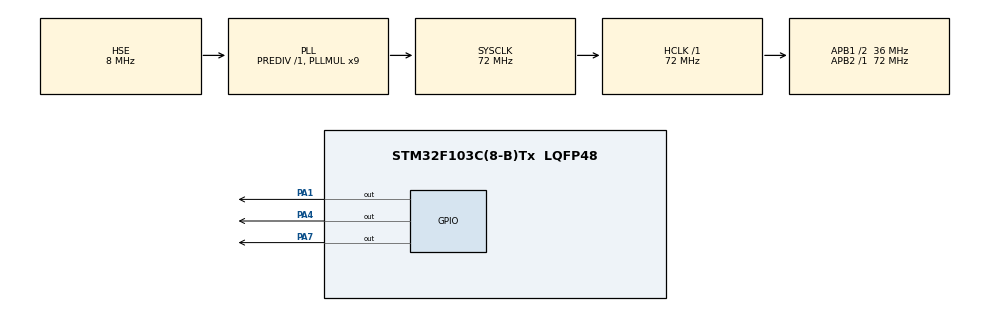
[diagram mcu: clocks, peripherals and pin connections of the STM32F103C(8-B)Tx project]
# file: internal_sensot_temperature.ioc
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ADC1.Channel-0\#ChannelRegularConversion=ADC_CHANNEL_TEMPSENSOR
ADC1.ContinuousConvMode=ENABLE
ADC1.NbrOfConversionFlag=1
ADC1.Rank-0\#ChannelRegularConversion=1
ADC1.SamplingTime-0\#ChannelRegularConversion=ADC_SAMPLETIME_55CYCLES_5
ADC1.master=1
Mcu.Family=STM32F1
Mcu.Name=STM32F103C(8-B)Tx
Mcu.Package=LQFP48
NVIC.PriorityGroup=NVIC_PRIORITYGROUP_4
PA1.Signal=GPIO_Output
PA13.Mode=Serial_Wire
PA13.Signal=SYS_JTMS-SWDIO
PA14.Mode=Serial_Wire
PA14.Signal=SYS_JTCK-SWCLK
PA4.Signal=GPIO_Output
PA7.Signal=GPIO_Output
PD0-OSC_IN.Mode=HSE-External-Oscillator
PD0-OSC_IN.Signal=RCC_OSC_IN
PD1-OSC_OUT.Mode=HSE-External-Oscillator
PD1-OSC_OUT.Signal=RCC_OSC_OUT
ProjectManager.HeapSize=0x200
ProjectManager.StackSize=0x400
ProjectManager.TargetToolchain=STM32CubeIDE
RCC.ADCPresc=RCC_ADCPCLK2_DIV6
RCC.AHBFreq_Value=72000000
RCC.APB1CLKDivider=RCC_HCLK_DIV2
RCC.APB1Freq_Value=36000000
RCC.APB1TimFreq_Value=72000000
RCC.APB2Freq_Value=72000000
RCC.APB2TimFreq_Value=72000000
RCC.HCLKFreq_Value=72000000
RCC.PLLMUL=RCC_PLL_MUL9
RCC.PLLSourceVirtual=RCC_PLLSOURCE_HSE
RCC.SYSCLKFreq_VALUE=72000000
RCC.SYSCLKSource=RCC_SYSCLKSOURCE_PLLCLK
RCC.USBFreq_Value=72000000
VP_ADC1_TempSens_Input.Mode=IN-TempSens
VP_ADC1_Vref_Input.Mode=IN-Vrefint
board=custom

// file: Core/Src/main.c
#include "main.h"

ADC_HandleTypeDef hadc1;

/* USER CODE BEGIN PV */
// Variables to store ADC reading and calculated temperatures
uint16_t readValue; // Value read from ADC
float tCelsius; // Temperature in degrees Celsius
float tFahrenheit; // Temperature in degrees Fahrenheit

/* USER CODE END PV */

void SystemClock_Config(void);
static void MX_GPIO_Init(void);
static void MX_ADC1_Init(void);

int main(void)
{

  /* MCU Configuration--------------------------------------------------------*/

  /* Reset of all peripherals, Initializes the Flash interface and the Systick. */
  HAL_Init();

  /* Configure the system clock */
  SystemClock_Config();

  /* Initialize all configured peripherals */
  MX_GPIO_Init();
  MX_ADC1_Init();
  /* USER CODE BEGIN 2 */

  // Start ADC
  HAL_ADC_Start(&hadc1);

  /* USER CODE END 2 */

  /* Infinite loop */
  /* USER CODE BEGIN WHILE */
  while (1)
  {
    // Wait for ADC to complete conversion
    HAL_ADC_PollForConversion(&hadc1, 1000);

    // Get the ADC reading and adjust by adding 60
    readValue = HAL_ADC_GetValue(&hadc1) + 60;

    // Calculate temperature in Celsius and Fahrenheit using linear formulas
    tCelsius = 357.558 - 0.187364 * readValue;
    tFahrenheit = 675.6 - 0.337255 * readValue;

    // Determine LED state based on ADC reading
    if (readValue > 1740) // High-temperature condition
    {
      HAL_GPIO_WritePin(GPIOA, GPIO_PIN_7, 1); // Red LED ON
      HAL_GPIO_WritePin(GPIOA, GPIO_PIN_4, 0); // Green LED OFF
      HAL_GPIO_WritePin(GPIOA, GPIO_PIN_1, 0); // Blue LED OFF
    }
    else if (readValue > 1720) // Medium-temperature condition
    {
      HAL_GPIO_WritePin(GPIOA, GPIO_PIN_7, 0); // Red LED OFF
      HAL_GPIO_WritePin(GPIOA, GPIO_PIN_4, 1); // Green LED ON
      HAL_GPIO_WritePin(GPIOA, GPIO_PIN_1, 0); // Blue LED OFF
    }
    else // Low-temperature condition
    {
      HAL_GPIO_WritePin(GPIOA, GPIO_PIN_7, 0); // Red LED OFF
      HAL_GPIO_WritePin(GPIOA, GPIO_PIN_4, 0); // Green LED OFF
      HAL_GPIO_WritePin(GPIOA, GPIO_PIN_1, 1); // Blue LED ON
    }

    // Wait 100 ms before the next reading
    HAL_Delay(100);

    /* USER CODE END WHILE */

  }
}

void SystemClock_Config(void)
{
  RCC_OscInitTypeDef RCC_OscInitStruct = {0};
  RCC_ClkInitTypeDef RCC_ClkInitStruct = {0};
  RCC_PeriphCLKInitTypeDef PeriphClkInit = {0};

  /** Initializes the RCC Oscillators according to the specified parameters
  * in the RCC_OscInitTypeDef structure.
  */
  RCC_OscInitStruct.OscillatorType = RCC_OSCILLATORTYPE_HSE;
  RCC_OscInitStruct.HSEState = RCC_HSE_ON;
  RCC_OscInitStruct.HSEPredivValue = RCC_HSE_PREDIV_DIV1;
  RCC_OscInitStruct.HSIState = RCC_HSI_ON;
  RCC_OscInitStruct.PLL.PLLState = RCC_PLL_ON;
  RCC_OscInitStruct.PLL.PLLSource = RCC_PLLSOURCE_HSE;
  RCC_OscInitStruct.PLL.PLLMUL = RCC_PLL_MUL9;
  if (HAL_RCC_OscConfig(&RCC_OscInitStruct) != HAL_OK)
  {
    Error_Handler();
  }

  /** Initializes the CPU, AHB and APB buses clocks
  */
  RCC_ClkInitStruct.ClockType = RCC_CLOCKTYPE_HCLK|RCC_CLOCKTYPE_SYSCLK
                              |RCC_CLOCKTYPE_PCLK1|RCC_CLOCKTYPE_PCLK2;
  RCC_ClkInitStruct.SYSCLKSource = RCC_SYSCLKSOURCE_PLLCLK;
  RCC_ClkInitStruct.AHBCLKDivider = RCC_SYSCLK_DIV1;
  RCC_ClkInitStruct.APB1CLKDivider = RCC_HCLK_DIV2;
  RCC_ClkInitStruct.APB2CLKDivider = RCC_HCLK_DIV1;

  if (HAL_RCC_ClockConfig(&RCC_ClkInitStruct, FLASH_LATENCY_2) != HAL_OK)
  {
    Error_Handler();
  }
  PeriphClkInit.PeriphClockSelection = RCC_PERIPHCLK_ADC;
  PeriphClkInit.AdcClockSelection = RCC_ADCPCLK2_DIV6;
  if (HAL_RCCEx_PeriphCLKConfig(&PeriphClkInit) != HAL_OK)
  {
    Error_Handler();
  }
}

static void MX_ADC1_Init(void)
{

  ADC_ChannelConfTypeDef sConfig = {0};

  /** Common config
  */
  hadc1.Instance = ADC1;
  hadc1.Init.ScanConvMode = ADC_SCAN_DISABLE;
  hadc1.Init.ContinuousConvMode = ENABLE;
  hadc1.Init.DiscontinuousConvMode = DISABLE;
  hadc1.Init.ExternalTrigConv = ADC_SOFTWARE_START;
  hadc1.Init.DataAlign = ADC_DATAALIGN_RIGHT;
  hadc1.Init.NbrOfConversion = 1;
  if (HAL_ADC_Init(&hadc1) != HAL_OK)
  {
    Error_Handler();
  }

  /** Configure Regular Channel
  */
  sConfig.Channel = ADC_CHANNEL_TEMPSENSOR;
  sConfig.Rank = ADC_REGULAR_RANK_1;
  sConfig.SamplingTime = ADC_SAMPLETIME_55CYCLES_5;
  if (HAL_ADC_ConfigChannel(&hadc1, &sConfig) != HAL_OK)
  {
    Error_Handler();
  }

}

static void MX_GPIO_Init(void)
{
  GPIO_InitTypeDef GPIO_InitStruct = {0};

  /* GPIO Ports Clock Enable */
  __HAL_RCC_GPIOD_CLK_ENABLE();
  __HAL_RCC_GPIOA_CLK_ENABLE();

  /*Configure GPIO pin Output Level */
  HAL_GPIO_WritePin(GPIOA, GPIO_PIN_1|GPIO_PIN_4|GPIO_PIN_7, GPIO_PIN_RESET);

  /*Configure GPIO pins : PA1 PA4 PA7 */
  GPIO_InitStruct.Pin = GPIO_PIN_1|GPIO_PIN_4|GPIO_PIN_7;
  GPIO_InitStruct.Mode = GPIO_MODE_OUTPUT_PP;
  GPIO_InitStruct.Pull = GPIO_NOPULL;
  GPIO_InitStruct.Speed = GPIO_SPEED_FREQ_LOW;
  HAL_GPIO_Init(GPIOA, &GPIO_InitStruct);

}

void Error_Handler(void)
{
  __disable_irq();
  while (1)
  {
  }
}
